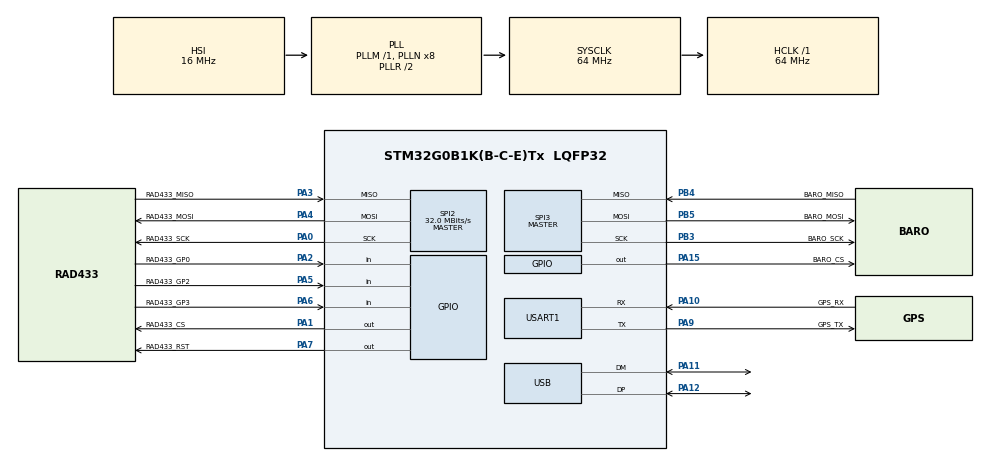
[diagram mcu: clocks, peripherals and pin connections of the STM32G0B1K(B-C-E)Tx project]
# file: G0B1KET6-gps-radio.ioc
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Dma.Request0=USART1_RX
Dma.USART1_RX.0.Direction=DMA_PERIPH_TO_MEMORY
Dma.USART1_RX.0.EventEnable=DISABLE
Dma.USART1_RX.0.Instance=DMA1_Channel1
Dma.USART1_RX.0.MemDataAlignment=DMA_MDATAALIGN_BYTE
Dma.USART1_RX.0.MemInc=DMA_MINC_ENABLE
Dma.USART1_RX.0.Mode=DMA_CIRCULAR
Dma.USART1_RX.0.PeriphDataAlignment=DMA_PDATAALIGN_BYTE
Dma.USART1_RX.0.PeriphInc=DMA_PINC_DISABLE
Dma.USART1_RX.0.Polarity=HAL_DMAMUX_REQ_GEN_RISING
Dma.USART1_RX.0.Priority=DMA_PRIORITY_LOW
Dma.USART1_RX.0.RequestNumber=1
Dma.USART1_RX.0.SignalID=NONE
Dma.USART1_RX.0.SyncEnable=DISABLE
Dma.USART1_RX.0.SyncPolarity=HAL_DMAMUX_SYNC_NO_EVENT
Dma.USART1_RX.0.SyncRequestNumber=1
Dma.USART1_RX.0.SyncSignalID=NONE
IWDG.Prescaler=IWDG_PRESCALER_128
IWDG.Reload=1249
Mcu.Family=STM32G0
Mcu.Name=STM32G0B1K(B-C-E)Tx
Mcu.Package=LQFP32
NVIC.DMA1_Channel1_IRQn=true\:0\:0\:false\:false\:true\:false\:true\:true
NVIC.USART1_IRQn=true\:0\:0\:false\:false\:true\:true\:true\:true
PA0.GPIO_Label=RAD433_SCK
PA0.Mode=Full_Duplex_Master
PA0.Signal=SPI2_SCK
PA1.GPIO_Label=RAD433_CS
PA1.Signal=GPIO_Output
PA10.GPIO_Label=GPS_RX
PA10.Mode=Asynchronous
PA10.Signal=USART1_RX
PA11\ [PA9].Mode=Device
PA11\ [PA9].Signal=USB_DM
PA12\ [PA10].Mode=Device
PA12\ [PA10].Signal=USB_DP
PA13.Mode=Serial_Wire
PA13.Signal=SYS_SWDIO
PA14-BOOT0.Mode=Serial_Wire
PA14-BOOT0.Signal=SYS_SWCLK
PA15.GPIO_Label=BARO_CS
PA15.Signal=GPIO_Output
PA2.GPIO_Label=RAD433_GP0
PA2.Signal=GPIO_Input
PA3.GPIO_Label=RAD433_MISO
PA3.Mode=Full_Duplex_Master
PA3.Signal=SPI2_MISO
PA4.GPIO_Label=RAD433_MOSI
PA4.Mode=Full_Duplex_Master
PA4.Signal=SPI2_MOSI
PA5.GPIO_Label=RAD433_GP2
PA5.Signal=GPIO_Input
PA6.GPIO_Label=RAD433_GP3
PA6.Signal=GPIO_Input
PA7.GPIO_Label=RAD433_RST
PA7.Signal=GPIO_Output
PA9.GPIO_Label=GPS_TX
PA9.Mode=Asynchronous
PA9.Signal=USART1_TX
PB3.GPIO_Label=BARO_SCK
PB3.Mode=Full_Duplex_Master
PB3.Signal=SPI3_SCK
PB4.GPIO_Label=BARO_MISO
PB4.Mode=Full_Duplex_Master
PB4.Signal=SPI3_MISO
PB5.GPIO_Label=BARO_MOSI
PB5.Mode=Full_Duplex_Master
PB5.Signal=SPI3_MOSI
ProjectManager.HeapSize=0x200
ProjectManager.StackSize=0x400
ProjectManager.TargetToolchain=STM32CubeIDE
RCC.ADCFreq_Value=64000000
RCC.AHBFreq_Value=64000000
RCC.CortexFreq_Value=64000000
RCC.EXTERNAL_CLOCK_VALUE=48000
RCC.HCLKFreq_Value=64000000
RCC.HSE_VALUE=8000000
RCC.HSI48_VALUE=48000000
RCC.HSI_VALUE=16000000
RCC.LSE_VALUE=32768
RCC.SYSCLKFreq_VALUE=64000000
RCC.SYSCLKSource=RCC_SYSCLKSOURCE_PLLCLK
RCC.USBFreq_Value=48000000
RCC.VCOOutputFreq_Value=128000000
SPI2.CalculateBaudRate=32.0 MBits/s
SPI2.Direction=SPI_DIRECTION_2LINES
SPI2.Mode=SPI_MODE_MASTER
SPI2.VirtualType=VM_MASTER
SPI3.Direction=SPI_DIRECTION_2LINES
SPI3.Mode=SPI_MODE_MASTER
SPI3.VirtualType=VM_MASTER
USART1.VirtualMode-Asynchronous=VM_ASYNC
USB_DEVICE.CLASS_NAME_FS=CDC
USB_DEVICE.VirtualMode=Cdc
USB_DEVICE.VirtualModeFS=Cdc_FS
VP_IWDG_VS_IWDG.Mode=IWDG_Activate
VP_SYS_VS_DBSignals.Mode=DisableDeadBatterySignals
VP_USB_DEVICE_VS_USB_DEVICE_CDC_FS.Mode=CDC_FS
board=custom

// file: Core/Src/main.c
/* USER CODE BEGIN Header */
/**
  ******************************************************************************
  * @file           : main.c
  * @brief          : Main program body
  ******************************************************************************
  * @attention
  *
  * Copyright (c) 2022 STMicroelectronics.
  * All rights reserved.
  *
  * This software is licensed under terms that can be found in the LICENSE file
  * in the root directory of this software component.
  * If no LICENSE file comes with this software, it is provided AS-IS.
  *
  ******************************************************************************
  */
/* USER CODE END Header */
#include "main.h"
#include "dma.h"
#include "iwdg.h"
#include "spi.h"
#include "usart.h"
#include "usb_device.h"
#include "gpio.h"

/* USER CODE BEGIN Includes */
#include "hardware_manager.h"
/* USER CODE END Includes */

void SystemClock_Config(void);

int main(void)
{

  /* MCU Configuration--------------------------------------------------------*/

  /* Reset of all peripherals, Initializes the Flash interface and the Systick. */
  HAL_Init();

  /* Configure the system clock */
  SystemClock_Config();

  /* Initialize all configured peripherals */
  MX_GPIO_Init();
  MX_DMA_Init();
  MX_SPI2_Init();
  MX_SPI3_Init();
  MX_USART1_UART_Init();
  MX_IWDG_Init();
  MX_USB_Device_Init();
  /* USER CODE BEGIN 2 */

  HM_HardwareInit();
  RadioManager_init();

  /* USER CODE END 2 */

  /* Infinite loop */
  /* USER CODE BEGIN WHILE */
  while (1)
  {

	HM_IWDG_Refresh();
	HM_ReadSensorData();
	HM_RadioUpdate();
	RadioManager_tick();

    /* USER CODE END WHILE */

  }
}

void SystemClock_Config(void)
{
  RCC_OscInitTypeDef RCC_OscInitStruct = {0};
  RCC_ClkInitTypeDef RCC_ClkInitStruct = {0};

  /** Configure the main internal regulator output voltage
  */
  HAL_PWREx_ControlVoltageScaling(PWR_REGULATOR_VOLTAGE_SCALE1);

  /** Initializes the RCC Oscillators according to the specified parameters
  * in the RCC_OscInitTypeDef structure.
  */
  RCC_OscInitStruct.OscillatorType = RCC_OSCILLATORTYPE_HSI|RCC_OSCILLATORTYPE_LSI
                              |RCC_OSCILLATORTYPE_HSI48;
  RCC_OscInitStruct.HSIState = RCC_HSI_ON;
  RCC_OscInitStruct.HSI48State = RCC_HSI48_ON;
  RCC_OscInitStruct.HSIDiv = RCC_HSI_DIV1;
  RCC_OscInitStruct.HSICalibrationValue = RCC_HSICALIBRATION_DEFAULT;
  RCC_OscInitStruct.LSIState = RCC_LSI_ON;
  RCC_OscInitStruct.PLL.PLLState = RCC_PLL_ON;
  RCC_OscInitStruct.PLL.PLLSource = RCC_PLLSOURCE_HSI;
  RCC_OscInitStruct.PLL.PLLM = RCC_PLLM_DIV1;
  RCC_OscInitStruct.PLL.PLLN = 8;
  RCC_OscInitStruct.PLL.PLLP = RCC_PLLP_DIV2;
  RCC_OscInitStruct.PLL.PLLQ = RCC_PLLQ_DIV2;
  RCC_OscInitStruct.PLL.PLLR = RCC_PLLR_DIV2;
  if (HAL_RCC_OscConfig(&RCC_OscInitStruct) != HAL_OK)
  {
    Error_Handler();
  }

  /** Initializes the CPU, AHB and APB buses clocks
  */
  RCC_ClkInitStruct.ClockType = RCC_CLOCKTYPE_HCLK|RCC_CLOCKTYPE_SYSCLK
                              |RCC_CLOCKTYPE_PCLK1;
  RCC_ClkInitStruct.SYSCLKSource = RCC_SYSCLKSOURCE_PLLCLK;
  RCC_ClkInitStruct.AHBCLKDivider = RCC_SYSCLK_DIV1;
  RCC_ClkInitStruct.APB1CLKDivider = RCC_HCLK_DIV1;

  if (HAL_RCC_ClockConfig(&RCC_ClkInitStruct, FLASH_LATENCY_2) != HAL_OK)
  {
    Error_Handler();
  }
}

void Error_Handler(void)
{
  __disable_irq();
  while (1)
  {
  }
}
